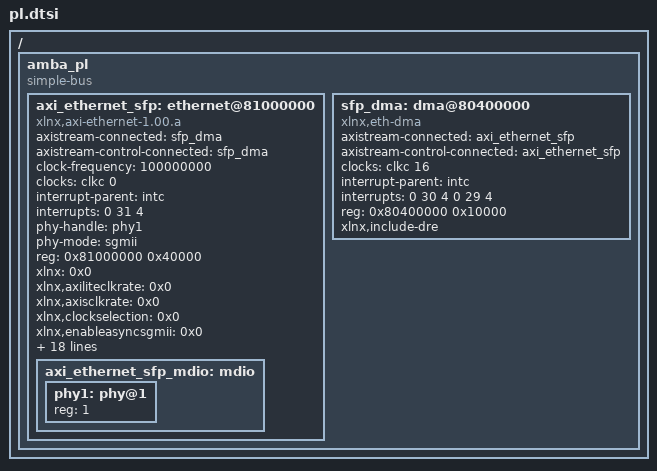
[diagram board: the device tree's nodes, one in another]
/*
 * CAUTION: This file is automatically generated by Xilinx.
 * Version:  
 * Today is: Thu Jan 31 13:26:50 2019
 */


/ {
	amba_pl: amba_pl {
		#address-cells = <1>;
		#size-cells = <1>;
		compatible = "simple-bus";
		ranges ;
		axi_ethernet_sfp: ethernet@81000000 {
			axistream-connected = <&sfp_dma>;
			axistream-control-connected = <&sfp_dma>;
			clock-frequency = <100000000>;
			clock-names = "ref_clk";
			clocks = <&clkc 0>;
			compatible = "xlnx,axi-ethernet-1.00.a";
			device_type = "network";
			interrupt-names = "interrupt";
			interrupt-parent = <&intc>;
			interrupts = <0 31 4>;
			phy-handle = <&phy1>;
			phy-mode = "sgmii";
			reg = <0x81000000 0x40000>;
			xlnx = <0x0>;
			xlnx,axiliteclkrate = <0x0>;
			xlnx,axisclkrate = <0x0>;
			xlnx,clockselection = <0x0>;
			xlnx,enableasyncsgmii = <0x0>;
			xlnx,gt-type = <0x0>;
			xlnx,gtinex = <0x0>;
			xlnx,gtlocation = <0x0>;
			xlnx,gtrefclksrc = <0x0>;
			xlnx,include-dre ;
			xlnx,instantiatebitslice0 = <0x0>;
			xlnx,phy-type = <0x5>;
			xlnx,phyaddr = <0x1>;
			xlnx,rable = <0x0>;
			xlnx,rxcsum = <0x0>;
			xlnx,rxlane0-placement = <0x0>;
			xlnx,rxlane1-placement = <0x0>;
			xlnx,rxmem = <0x1000>;
			xlnx,rxnibblebitslice0used = <0x0>;
			xlnx,tx-in-upper-nibble = <0x1>;
			xlnx,txcsum = <0x0>;
			xlnx,txlane0-placement = <0x0>;
			xlnx,txlane1-placement = <0x0>;
			axi_ethernet_sfp_mdio: mdio {
				#address-cells = <1>;
				#size-cells = <0>;
				phy1: phy@1 {
					device_type = "ethernet-phy";
					reg = <1>;
				};
			};
		};
		sfp_dma: dma@80400000 {
			#dma-cells = <1>;
			axistream-connected = <&axi_ethernet_sfp>;
			axistream-control-connected = <&axi_ethernet_sfp>;
			clock-names = "s_axi_lite_aclk";
			clocks = <&clkc 16>;
			compatible = "xlnx,eth-dma";
			interrupt-names = "mm2s_introut", "s2mm_introut";
			interrupt-parent = <&intc>;
			interrupts = <0 30 4 0 29 4>;
			reg = <0x80400000 0x10000>;
			xlnx,include-dre ;
		};
	};
};
